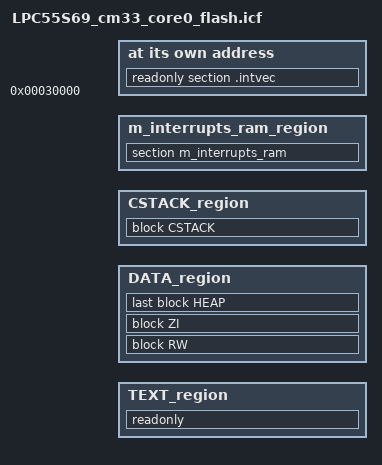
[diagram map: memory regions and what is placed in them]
/*
** ###################################################################
**     Processors:          LPC55S69JBD100_cm33_core0
**                          LPC55S69JET98_cm33_core0
**
**     Compiler:            IAR ANSI C/C++ Compiler for ARM
**     Reference manual:    LPC55xx/LPC55Sxx User manual Rev.0.2  15 Aug 2018
**     Version:             rev. 1.0, 2018-08-22
**     Build:               b180921
**
**     Abstract:
**         Linker file for the IAR ANSI C/C++ Compiler for ARM
**
**     Copyright 2016 Freescale Semiconductor, Inc.
**     Copyright 2016-2018 NXP
**     All rights reserved.
**
**     SPDX-License-Identifier: BSD-3-Clause
**
**     http:                 www.nxp.com
**     mail:                 support@nxp.com
**
** ###################################################################
*/

define symbol NS_CODE_START = 0x00030000;
define symbol NS_CODE_SIZE  = 0x00068000;
define symbol NS_DATA_START = 0x20022000;
define symbol NS_DATA_SIZE  = 0x00022000;

define symbol __ram_vector_table__ = 1;

if (!isdefinedsymbol(MBED_ROM_START)) {
  define symbol MBED_ROM_START         = NS_CODE_START;
}

if (!isdefinedsymbol(MBED_APP_START)) {
  define symbol MBED_APP_START         = MBED_ROM_START;
}

if (!isdefinedsymbol(MBED_ROM_SIZE)) {
  define symbol MBED_ROM_SIZE          = NS_CODE_SIZE;
}

if (!isdefinedsymbol(MBED_APP_SIZE)) {
  define symbol MBED_APP_SIZE          = MBED_ROM_SIZE;
}

if (!isdefinedsymbol(MBED_RAM_START)) {
  define symbol MBED_RAM_START         = NS_DATA_START;
}

if (!isdefinedsymbol(MBED_RAM_SIZE)) {
  define symbol MBED_RAM_SIZE          = NS_DATA_SIZE;
}

if (!isdefinedsymbol(MBED_BOOT_STACK_SIZE)) {
  define symbol MBED_BOOT_STACK_SIZE   = 0x400;
}

define symbol __stack_size__ = MBED_BOOT_STACK_SIZE;
define symbol __heap_size__  = 0x4000;

define symbol __ram_vector_table_size__   =  isdefinedsymbol(__ram_vector_table__) ? 0x00000200 : 0;
define symbol __ram_vector_table_offset__ =  isdefinedsymbol(__ram_vector_table__) ? 0x000001FF : 0;

/* USB BDT size */
define symbol usb_bdt_size             = 0x0;

/* Stack and Heap Sizes */
if (isdefinedsymbol(__stack_size__)) {
  define symbol __size_cstack__        = __stack_size__;
} else {
  define symbol __size_cstack__        = 0x0400;
}

if (isdefinedsymbol(__heap_size__)) {
  define symbol __size_heap__          = __heap_size__;
} else {
  define symbol __size_heap__          = 0x0400;
}

if (!isdefinedsymbol(NVIC_INTERRUPT_NUM)) {
  define symbol NVIC_INTERRUPT_NUM   = 60;
}

if (!isdefinedsymbol(EXCEPTION_VECT_NUM)) {
  define symbol EXCEPTION_VECT_NUM   = 16;
}

if (!isdefinedsymbol(MEMORY_ADDR_SIZE_IN_BYTE)) {
  define symbol MEMORY_ADDR_SIZE_IN_BYTE   = 4;
}

if (!isdefinedsymbol(MBED_INTERRUPTS_SIZE)) {
  define symbol MBED_INTERRUPTS_SIZE   = ((NVIC_INTERRUPT_NUM + EXCEPTION_VECT_NUM) * MEMORY_ADDR_SIZE_IN_BYTE);
}

define symbol m_interrupts_start     = MBED_APP_START;
define symbol m_interrupts_end       = (MBED_APP_START + (MBED_INTERRUPTS_SIZE - 1));

define symbol m_text_start           = (MBED_APP_START + MBED_INTERRUPTS_SIZE);
define symbol m_text_end             = (MBED_APP_START + MBED_APP_SIZE - 1);

define symbol m_interrupts_ram_start = MBED_RAM_START;
define symbol m_interrupts_ram_end   = (MBED_RAM_START + __ram_vector_table_size__ - 1);

define symbol m_data_start           = (m_interrupts_ram_start + __ram_vector_table_size__);
define symbol m_data_end             = (MBED_RAM_START + MBED_RAM_SIZE - 1);

define symbol m_usb_sram_start       = 0x40100000;
define symbol m_usb_sram_end         = 0x00004000;


define exported symbol __VECTOR_TABLE  = m_interrupts_start;
define exported symbol __VECTOR_RAM    = isdefinedsymbol(__ram_vector_table__) ? m_interrupts_ram_start : m_interrupts_start;
define exported symbol __RAM_VECTOR_TABLE_SIZE = __ram_vector_table_size__;

define memory mem with size = 4G;

define region TEXT_region             = mem:[from m_interrupts_start to m_interrupts_end]
                                      | mem:[from m_text_start to m_text_end];
define region DATA_region = mem:[from m_data_start to m_data_end-__size_cstack__];
define region CSTACK_region = mem:[from m_data_end-__size_cstack__+1 to m_data_end];

define region m_interrupts_ram_region = mem:[from m_interrupts_ram_start to m_interrupts_ram_end];

define block CSTACK    with alignment = 8, size = __size_cstack__   { };
define block HEAP      with expanding size, alignment = 8, minimum size = __heap_size__ { };
define block RW        { readwrite };
define block ZI        { zi };

/* regions for USB */
define region USB_BDT_region = mem:[from m_usb_sram_start to m_usb_sram_start + usb_bdt_size - 1];
define region USB_SRAM_region = mem:[from m_usb_sram_start + usb_bdt_size to m_usb_sram_end];
place in USB_BDT_region                     { section m_usb_bdt };
place in USB_SRAM_region                    { section m_usb_global };

initialize by copy { readwrite, section .textrw };

if (isdefinedsymbol(__USE_DLIB_PERTHREAD))
{
  /* Required in a multi-threaded application */
  initialize by copy with packing = none { section __DLIB_PERTHREAD };
}

do not initialize  { section .noinit, section m_usb_bdt, section m_usb_global };

place at address mem: m_interrupts_start    { readonly section .intvec };
place in TEXT_region                        { readonly };
place in DATA_region                        { block RW };
place in DATA_region                        { block ZI };
place in DATA_region                        { last block HEAP };
place in CSTACK_region                      { block CSTACK };
place in m_interrupts_ram_region            { section m_interrupts_ram };

